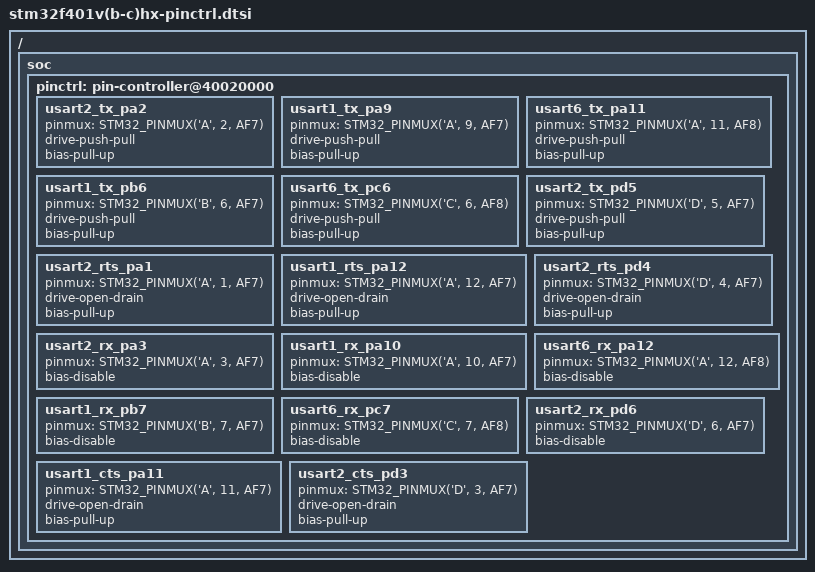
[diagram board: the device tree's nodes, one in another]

/*
 * NOTE: Autogenerated file using stm32_pinctrl_gen.py
 *
 * SPDX-License-Identifier: Apache-2.0
 */

#include <dt-bindings/pinctrl/stm32-pinctrl.h>

/ {
	soc {
		pinctrl: pin-controller@40020000 {
			/* UART_TX */
			usart2_tx_pa2: usart2_tx_pa2 {
				pinmux = <STM32_PINMUX('A', 2, AF7)>;
				drive-push-pull;
				bias-pull-up;
			};

			usart1_tx_pa9: usart1_tx_pa9 {
				pinmux = <STM32_PINMUX('A', 9, AF7)>;
				drive-push-pull;
				bias-pull-up;
			};

			usart6_tx_pa11: usart6_tx_pa11 {
				pinmux = <STM32_PINMUX('A', 11, AF8)>;
				drive-push-pull;
				bias-pull-up;
			};

			usart1_tx_pb6: usart1_tx_pb6 {
				pinmux = <STM32_PINMUX('B', 6, AF7)>;
				drive-push-pull;
				bias-pull-up;
			};

			usart6_tx_pc6: usart6_tx_pc6 {
				pinmux = <STM32_PINMUX('C', 6, AF8)>;
				drive-push-pull;
				bias-pull-up;
			};

			usart2_tx_pd5: usart2_tx_pd5 {
				pinmux = <STM32_PINMUX('D', 5, AF7)>;
				drive-push-pull;
				bias-pull-up;
			};


			/* UART_RTS */
			usart2_rts_pa1: usart2_rts_pa1 {
				pinmux = <STM32_PINMUX('A', 1, AF7)>;
				drive-open-drain;
				bias-pull-up;
			};

			usart1_rts_pa12: usart1_rts_pa12 {
				pinmux = <STM32_PINMUX('A', 12, AF7)>;
				drive-open-drain;
				bias-pull-up;
			};

			usart2_rts_pd4: usart2_rts_pd4 {
				pinmux = <STM32_PINMUX('D', 4, AF7)>;
				drive-open-drain;
				bias-pull-up;
			};


			/* UART_RX */
			usart2_rx_pa3: usart2_rx_pa3 {
				pinmux = <STM32_PINMUX('A', 3, AF7)>;
				bias-disable;
			};

			usart1_rx_pa10: usart1_rx_pa10 {
				pinmux = <STM32_PINMUX('A', 10, AF7)>;
				bias-disable;
			};

			usart6_rx_pa12: usart6_rx_pa12 {
				pinmux = <STM32_PINMUX('A', 12, AF8)>;
				bias-disable;
			};

			usart1_rx_pb7: usart1_rx_pb7 {
				pinmux = <STM32_PINMUX('B', 7, AF7)>;
				bias-disable;
			};

			usart6_rx_pc7: usart6_rx_pc7 {
				pinmux = <STM32_PINMUX('C', 7, AF8)>;
				bias-disable;
			};

			usart2_rx_pd6: usart2_rx_pd6 {
				pinmux = <STM32_PINMUX('D', 6, AF7)>;
				bias-disable;
			};


			/* UART_CTS */
			usart1_cts_pa11: usart1_cts_pa11 {
				pinmux = <STM32_PINMUX('A', 11, AF7)>;
				drive-open-drain;
				bias-pull-up;
			};

			usart2_cts_pd3: usart2_cts_pd3 {
				pinmux = <STM32_PINMUX('D', 3, AF7)>;
				drive-open-drain;
				bias-pull-up;
			};

		};
	};
};
